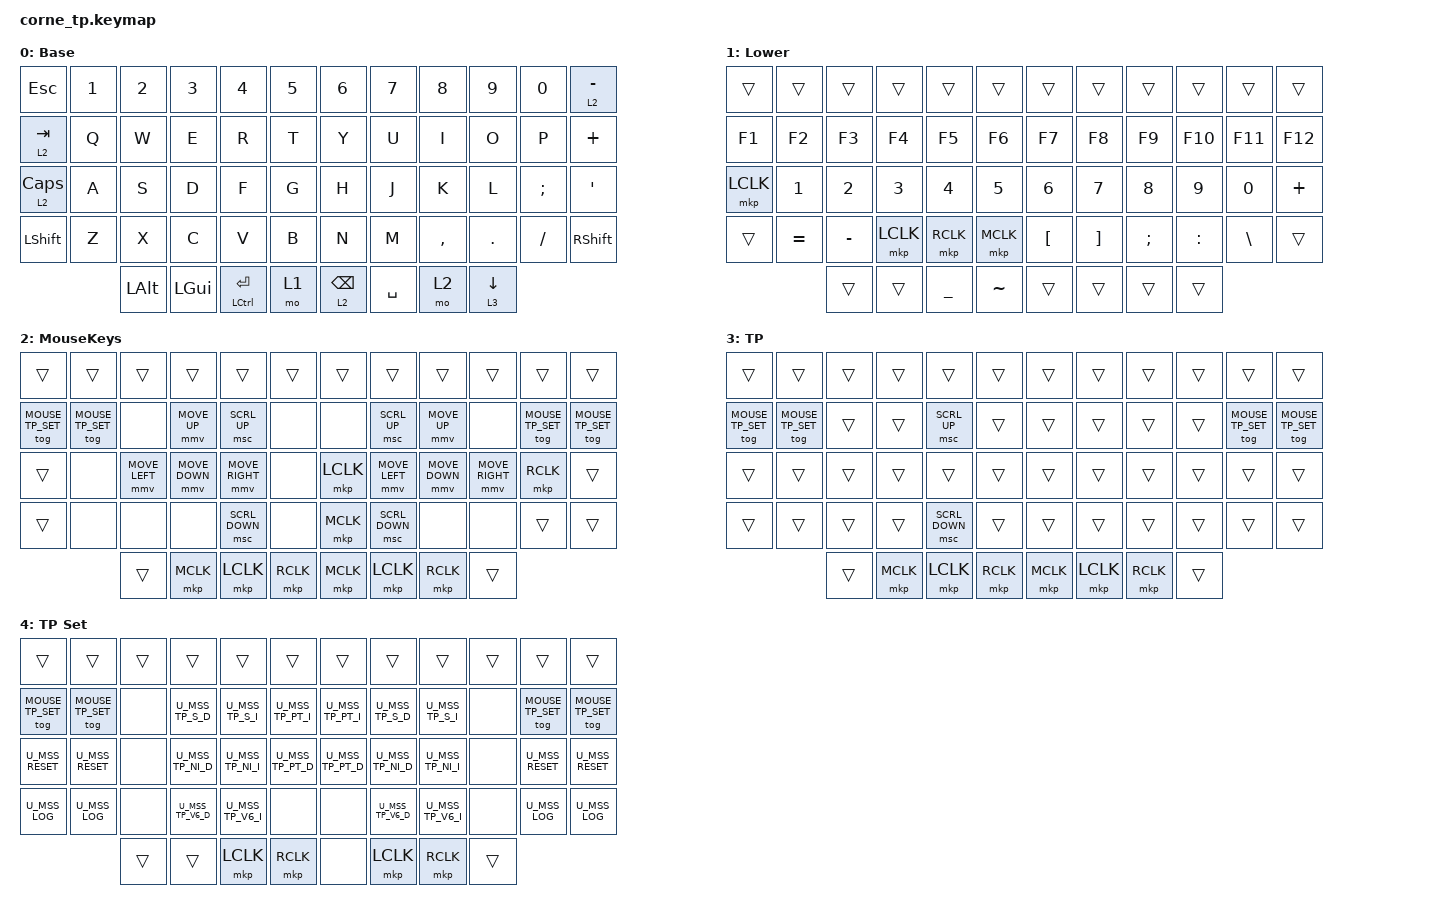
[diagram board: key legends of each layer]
/*
 * Copyright (c) 2020 The ZMK Contributors
 *
 * SPDX-License-Identifier: MIT
 */

#include <behaviors.dtsi>
#include <dt-bindings/zmk/keys.h>
#include <dt-bindings/zmk/bt.h>

#define BASE 0
#define LOWER 1
#define MOUSE_KEYS 2
#define MOUSE_TP 3
#define MOUSE_TP_SET 4

/*
 * Defines to enable/disable features
 *
 * These defines allow us to conditionally enable and disable parts of the keymap config.
 *
 * For example, if we decide to build the firmware without the mouse features, we can
 * disable all the config options that rely on those forks and modules without having
 * to edit the entire keymap file manually every time.
 */

#define HAS_MOUSE_KEYS
#define HAS_MOUSE_TP

#ifdef HAS_MOUSE_KEYS
  #include <dt-bindings/zmk/mouse.h>
  #include <behaviors/mouse_keys.dtsi>
#endif  // HAS_MOUSE_KEYS

#ifdef HAS_MOUSE_TP
  // We store the trackpoint settings in a separate file
  // to make organization a little easier.
  #include "include/mouse_tp.dtsi"
#endif  // HAS_MOUSE_TP

// Adjust layer keys based on enabled features.
//
// This prevents build errors when we build the firmware
// without the mouse keys PR or the TP module.
#ifdef HAS_MOUSE_KEYS
  #define U_THUMB_INNER &mo MOUSE_KEYS
#else
  #define U_THUMB_INNER &none
#endif  // HAS_MOUSE_KEYS

#ifdef HAS_MOUSE_TP
  #define U_TOG_TP_SET &tog MOUSE_TP_SET
#else
  #define U_TOG_TP_SET &none
#endif  // HAS_MOUSE_TP

// Disable line-wrap in your editor to see a "visualization" of the key layouts
/ {


combos {
        compatible = "zmk,combos";

        combo_lbrc {
            timeout-ms = <50>;
            key-positions = <16 17>; // KP: VB
            bindings = <&mt RBRC LBRC>; // }{
            layers = <0 1 2 3 4 5>;
        };

        combo_rbrc {
            timeout-ms = <50>;
            key-positions = <18 19>; // KP: NM
            bindings = <&kp RBRC>; // }
            layers = <0 1 2 3 4 5>;
        };

        combo_lpar {
            timeout-ms = <50>;
            key-positions = <28 29>; // KP: FG
            bindings = <&mt RPAR LPAR>; // )(
            layers = <0 1 2 3 4 5>;
        };

        combo_rpar {
            timeout-ms = <50>;
            key-positions = <30 31>; // KP: HJ
            bindings = <&kp RPAR>; // )
            layers = <0 1 2 3 4 5>;
        };

        combo_lbkt {
            timeout-ms = <50>;
            key-positions = <40 41>; // KP: RT
            bindings = <&mt RBKT LBKT>; // ][ // 可以用CMD+这个单手返回到代码上一个编辑的地方 或者网页返回
            layers = <0 1 2 3 4 5>;
        };

        combo_rbkt {
            timeout-ms = <50>;
            key-positions = <42 43>; // KP: YU
            bindings = <&kp RBKT>; // ]
            layers = <0 1 2 3 4 5>;
        };


        up {
            bindings = <&kp UP>;
            key-positions = <15 16>;
            layers = <0>;
            timeout-ms = <50>;
        };

        down {
            bindings = <&kp DOWN>;
            key-positions = <39 40>;
            timeout-ms = <50>;
            layers = <0>;
        };

        left {
            bindings = <&kp LEFT>;
            key-positions = <26 27>;
            layers = <0>;
            timeout-ms = <50>;
        };

        right {
            bindings = <&kp RIGHT>;
            key-positions = <27 28>;
            layers = <0>;
            timeout-ms = <50>;
        };
        reset_bootloader {
            bindings = <&bootloader>;
            key-positions = <36 37>;
            layers = <0>;
            timeout-ms = <50>;
        };

    

        rup {
            bindings = <&kp UP>;
            key-positions = <19 20>;
            layers = <0 1>;
            timeout-ms = <50>;
        };

        rdown {
            bindings = <&kp DOWN>;
            key-positions = <43 44>;
            timeout-ms = <50>;
        };

        rleft {
            bindings = <&kp LEFT>;
            key-positions = <31 32>;
            layers = <0 1>;
            timeout-ms = <50>;
        };

        rright {
            bindings = <&kp RIGHT>;
            key-positions = <32 33>;
            layers = <0 1>;
            timeout-ms = <50>;
        };

    };
  keymap {
    compatible = "zmk,keymap";

    Base_layer {
      display-name = "Base";
      bindings = <
     &kp ESC                  &kp N1                    &kp N2                    &kp N3                   &kp N4                   &kp N5                    &kp N6                        &kp N7                    &kp N8                 &kp N9                       &kp N0             &lt 2 MINUS
// ╭────────────────────────┬────────────────────────┬────────────────────────┬────────────────────────┬────────────────────────┬────────────────────────╮    ╭────────────────────────┬────────────────────────┬────────────────────────┬───────────────────────┬────────────────────────┬────────────────────────╮
     &lt 2 TAB                  &kp Q                    &kp W                    &kp E                    &kp R                    &kp T                         &kp Y                    &kp U                    &kp I                    &kp O                    &kp P                     &kp PLUS
// ├────────────────────────┼────────────────────────┼────────────────────────┼────────────────────────┼────────────────────────┼────────────────────────┤    ├────────────────────────┼────────────────────────┼────────────────────────┼───────────────────────┼────────────────────────┼────────────────────────┤
    &lt 2 CAPSLOCK                &kp A                    &kp S                    &kp D                    &kp F                    &kp G                         &kp H                    &kp J                    &kp K                    &kp L                    &kp SEMI                 &kp SQT
// ├────────────────────────┼────────────────────────┼────────────────────────┼────────────────────────┼────────────────────────┼────────────────────────┤    ├────────────────────────┼────────────────────────┼────────────────────────┼───────────────────────┼────────────────────────┼────────────────────────┤
     &kp LSHFT                &kp Z                    &kp X                    &kp C                    &kp V                    &kp B                         &kp N                    &kp M                    &kp COMMA                &kp DOT                  &kp FSLH                 &kp RSHFT
// ╰────────────────────────┴────────────────────────┴────────────────────────┴────────────────────────┼────────────────────────┼────────────────────────┤    ├────────────────────────┼────────────────────────┼────────────────────────┼───────────────────────┼────────────────────────┼────────────────────────╯
                                                          &kp LEFT_ALT             &kp LGUI               &mt LCTRL ENTER            &mo 1                       &lt 2 BACKSPACE             &kp SPACE               &mo 2                      &lt 3 DOWN                       
//                                                                            ╰────────────────────────┴────────────────────────┴────────────────────────╯    ╰────────────────────────┴────────────────────────┴────────────────────────╯

      >;
    };


    Lower_layer {
      display-name = "Lower";
      bindings = <
      &trans                       &trans                      &trans                    &trans                    &trans              &trans                     &trans                       &trans                      &trans                &trans                   &trans                 &trans
// ╭────────────────────────┬────────────────────────┬────────────────────────┬────────────────────────┬────────────────────────┬────────────────────────╮    ╭────────────────────────┬────────────────────────┬────────────────────────┬────────────────────────┬────────────────────────┬────────────────────────╮
     &kp F1                       &kp F2                        &kp F3               &kp F4                   &kp F5                  &kp F6                    &kp F7                         &kp F8                    &kp F9                 &kp F10                     &kp F11            &kp F12
// ├────────────────────────┼────────────────────────┼────────────────────────┼────────────────────────┼────────────────────────┼────────────────────────┤    ├────────────────────────┼────────────────────────┼────────────────────────┼────────────────────────┼────────────────────────┼────────────────────────┤
      &mkp LCLK                  &kp N1                    &kp N2                    &kp N3                   &kp N4                   &kp N5                    &kp N6                        &kp N7                    &kp N8                 &kp N9                       &kp N0             &kp PLUS
// ├────────────────────────┼────────────────────────┼────────────────────────┼────────────────────────┼────────────────────────┼────────────────────────┤    ├────────────────────────┼────────────────────────┼────────────────────────┼────────────────────────┼────────────────────────┼────────────────────────┤
     &trans                   &kp EQUAL                &kp MINUS               &mkp LCLK                &mkp RCLK            &mkp MCLK              &kp LEFT_BRACKET         &kp RIGHT_BRACKET        &kp SEMICOLON            &kp COLON                &kp BACKSLASH             &trans
// ╰────────────────────────┴────────────────────────┴────────────────────────┴────────────────────────┼────────────────────────┼────────────────────────┤    ├────────────────────────┼────────────────────────┼────────────────────────┼────────────────────────┴────────────────────────┼────────────────────────╯
                                                         &trans                 &trans                      &kp UNDERSCORE           &kp TILDE                                &trans                    &trans                 &trans               &trans
//                                                                            ╰────────────────────────┴────────────────────────┴────────────────────────╯    ╰────────────────────────┴────────────────────────┴────────────────────────╯
      >;
    };

#ifdef HAS_MOUSE_KEYS

    MouseKeys_layer {
      display-name = "MouseKeys";
      bindings = <
       &trans                       &trans                      &trans                    &trans                    &trans              &trans                     &trans                       &trans                      &trans                &trans                   &trans                 &trans
// ╭────────────────────────┬────────────────────────┬────────────────────────┬────────────────────────┬────────────────────────┬────────────────────────╮    ╭────────────────────────┬────────────────────────┬────────────────────────┬────────────────────────┬────────────────────────┬────────────────────────╮
     U_TOG_TP_SET             U_TOG_TP_SET             &none                    &mmv MOVE_UP             &msc SCRL_UP             &none                         &none                    &msc SCRL_UP             &mmv MOVE_UP             &none                    U_TOG_TP_SET              U_TOG_TP_SET
// ├────────────────────────┼────────────────────────┼────────────────────────┼────────────────────────┼────────────────────────┼────────────────────────┤    ├────────────────────────┼────────────────────────┼────────────────────────┼────────────────────────┼────────────────────────┼────────────────────────┤
     &trans                   &none                    &mmv MOVE_LEFT           &mmv MOVE_DOWN           &mmv MOVE_RIGHT          &none                         &mkp LCLK                     &mmv MOVE_LEFT           &mmv MOVE_DOWN           &mmv MOVE_RIGHT         &mkp RCLK                      &trans
// ├────────────────────────┼────────────────────────┼────────────────────────┼────────────────────────┼────────────────────────┼────────────────────────┤    ├────────────────────────┼────────────────────────┼────────────────────────┼────────────────────────┼────────────────────────┼────────────────────────┤
     &trans                   &none                    &none                    &none                    &msc SCRL_DOWN           &none                         &mkp MCLK                    &msc SCRL_DOWN           &none                    &none                    &trans                    &trans
// ╰────────────────────────┴────────────────────────┴────────────────────────┴────────────────────────┼────────────────────────┼────────────────────────┤    ├────────────────────────┼────────────────────────┼────────────────────────┼────────────────────────┴────────────────────────┼────────────────────────╯
                                                           &trans                 &mkp MCLK                &mkp LCLK                &mkp RCLK                     &mkp MCLK                &mkp LCLK                &mkp RCLK               &trans                
//                                                                            ╰────────────────────────┴────────────────────────┴────────────────────────╯    ╰────────────────────────┴────────────────────────┴────────────────────────╯
      >;
    };

#endif

#ifdef HAS_MOUSE_TP

    // Automatically activated when the mouse or trackpoint moves.
    // Configured in `include/mouse_tp.dtsi`.
    MouseTP_layer {
      display-name = "TP";
      bindings = <
       &trans                       &trans                      &trans                    &trans                    &trans              &trans                     &trans                       &trans                      &trans                &trans                   &trans                 &trans
// ╭────────────────────────┬────────────────────────┬────────────────────────┬────────────────────────┬────────────────────────┬────────────────────────╮    ╭────────────────────────┬────────────────────────┬────────────────────────┬────────────────────────┬────────────────────────┬────────────────────────╮
     U_TOG_TP_SET             U_TOG_TP_SET             &trans                   &trans                   &msc SCRL_UP             &trans                        &trans                   &trans                   &trans                   &trans                   U_TOG_TP_SET              U_TOG_TP_SET
// ├────────────────────────┼────────────────────────┼────────────────────────┼────────────────────────┼────────────────────────┼────────────────────────┤    ├────────────────────────┼────────────────────────┼────────────────────────┼────────────────────────┼────────────────────────┼────────────────────────┤
     &trans                   &trans                   &trans                   &trans                   &trans                   &trans                        &trans                   &trans                   &trans                   &trans                   &trans                    &trans
// ├────────────────────────┼────────────────────────┼────────────────────────┼────────────────────────┼────────────────────────┼────────────────────────┤    ├────────────────────────┼────────────────────────┼────────────────────────┼────────────────────────┼────────────────────────┼────────────────────────┤
     &trans                   &trans                   &trans                   &trans                   &msc SCRL_DOWN           &trans                        &trans                   &trans                   &trans                   &trans                   &trans                    &trans
// ╰────────────────────────┴────────────────────────┴────────────────────────┴────────────────────────┼────────────────────────┼────────────────────────┤    ├────────────────────────┼────────────────────────┼────────────────────────┼────────────────────────┴────────────────────────┼────────────────────────╯
                                                          &trans             &mkp MCLK                &mkp LCLK                &mkp RCLK                     &mkp MCLK                &mkp LCLK                &mkp RCLK            &trans          
//                                                                            ╰────────────────────────┴────────────────────────┴────────────────────────╯    ╰────────────────────────┴────────────────────────┴────────────────────────╯
      >;
    };

    // You can find the defines for the actual key press behaviors in `include/mouse_tp.dtsi`.
    MouseSettings_layer {
      display-name = "TP Set";
      bindings = <
       &trans                       &trans                      &trans                    &trans                    &trans              &trans                     &trans                       &trans                      &trans                &trans                   &trans                 &trans
// ╭────────────────────────┬────────────────────────┬────────────────────────┬────────────────────────┬────────────────────────┬────────────────────────╮    ╭────────────────────────┬────────────────────────┬────────────────────────┬────────────────────────┬────────────────────────┬────────────────────────╮
     U_TOG_TP_SET             U_TOG_TP_SET             &none                    U_MSS_TP_S_D             U_MSS_TP_S_I             U_MSS_TP_PT_I                 U_MSS_TP_PT_I            U_MSS_TP_S_D             U_MSS_TP_S_I             &none                    U_TOG_TP_SET              U_TOG_TP_SET
// ├────────────────────────┼────────────────────────┼────────────────────────┼────────────────────────┼────────────────────────┼────────────────────────┤    ├────────────────────────┼────────────────────────┼────────────────────────┼────────────────────────┼────────────────────────┼────────────────────────┤
     U_MSS_RESET              U_MSS_RESET              &none                    U_MSS_TP_NI_D            U_MSS_TP_NI_I            U_MSS_TP_PT_D                 U_MSS_TP_PT_D            U_MSS_TP_NI_D            U_MSS_TP_NI_I            &none                    U_MSS_RESET               U_MSS_RESET
// ├────────────────────────┼────────────────────────┼────────────────────────┼────────────────────────┼────────────────────────┼────────────────────────┤    ├────────────────────────┼────────────────────────┼────────────────────────┼────────────────────────┼────────────────────────┼────────────────────────┤
     U_MSS_LOG                U_MSS_LOG                &none                    U_MSS_TP_V6_D            U_MSS_TP_V6_I            &none                         &none                    U_MSS_TP_V6_D            U_MSS_TP_V6_I            &none                    U_MSS_LOG                 U_MSS_LOG
// ╰────────────────────────┴────────────────────────┴────────────────────────┴────────────────────────┼────────────────────────┼────────────────────────┤    ├────────────────────────┼────────────────────────┼────────────────────────┼────────────────────────┴────────────────────────┼────────────────────────╯
                                                        &trans                         &trans                   &mkp LCLK                &mkp RCLK                     &none                    &mkp LCLK                &mkp RCLK        &trans      
//                                                                            ╰────────────────────────┴────────────────────────┴────────────────────────╯    ╰────────────────────────┴────────────────────────┴────────────────────────╯
      >;
    };

#endif
  };
};
